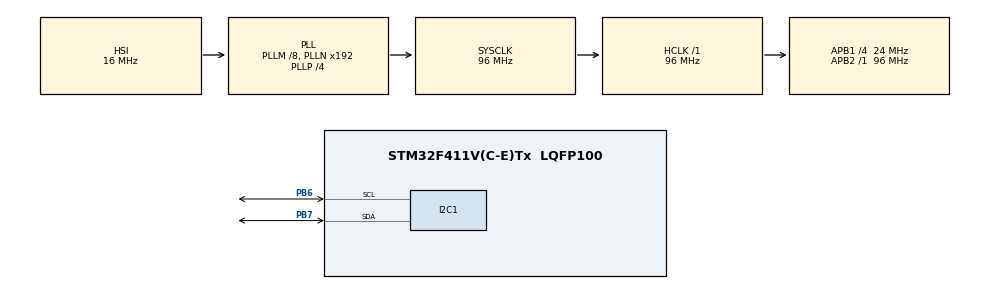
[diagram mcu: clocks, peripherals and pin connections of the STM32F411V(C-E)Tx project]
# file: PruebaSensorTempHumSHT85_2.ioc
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Mcu.Family=STM32F4
Mcu.Name=STM32F411V(C-E)Tx
Mcu.Package=LQFP100
NVIC.PriorityGroup=NVIC_PRIORITYGROUP_0
PB6.GPIO_Pu=GPIO_PULLUP
PB6.Mode=I2C
PB6.Signal=I2C1_SCL
PB7.GPIO_Pu=GPIO_PULLUP
PB7.Mode=I2C
PB7.Signal=I2C1_SDA
ProjectManager.HeapSize=0x200
ProjectManager.StackSize=0x400
ProjectManager.TargetToolchain=STM32CubeIDE
RCC.48MHZClocksFreq_Value=48000000
RCC.AHBFreq_Value=96000000
RCC.APB1CLKDivider=RCC_HCLK_DIV4
RCC.APB1Freq_Value=24000000
RCC.APB1TimFreq_Value=48000000
RCC.APB2Freq_Value=96000000
RCC.APB2TimFreq_Value=96000000
RCC.CortexFreq_Value=96000000
RCC.HCLKFreq_Value=96000000
RCC.HSE_VALUE=8000000
RCC.HSI_VALUE=16000000
RCC.PLLI2SM=5
RCC.PLLI2SN=200
RCC.PLLM=8
RCC.PLLP=RCC_PLLP_DIV4
RCC.PLLQ=8
RCC.SYSCLKFreq_VALUE=96000000
RCC.SYSCLKSource=RCC_SYSCLKSOURCE_PLLCLK
RCC.VCOOutputFreq_Value=384000000
board=STM32F411E-DISCO

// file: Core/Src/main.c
/* USER CODE BEGIN Header */
/* USER CODE END Header */
#include "main.h"

/* USER CODE BEGIN Includes */
#include <stdio.h>
/* USER CODE END Includes */

/* USER CODE BEGIN PD */
// Dirección I2C del SHT85 (ver datasheet para confirmar)
#define SHT85_I2C_ADDR 0x44 << 1 // Cambia si usas otra configuración

// Comando para iniciar la medición
#define SHT85_CMD_MEASURE_HIGHREP 0x2400
/* USER CODE END PD */

I2C_HandleTypeDef hi2c1;

/* USER CODE BEGIN PV */
// Variables globales para Live Expressions
float temperature = 0.0f;
float humidity = 0.0f;
uint16_t temp_raw = 0, hum_raw = 0;
/* USER CODE END PV */

void SystemClock_Config(void);
static void MX_GPIO_Init(void);
static void MX_I2C1_Init(void);
/* USER CODE BEGIN PFP */
void ReadSHT85(float *temperature, float *humidity) {
    uint8_t cmd[2] = {SHT85_CMD_MEASURE_HIGHREP >> 8, SHT85_CMD_MEASURE_HIGHREP & 0xFF};
    uint8_t data[6];

    // Enviar el comando para iniciar la medición
    HAL_I2C_Master_Transmit(&hi2c1, SHT85_I2C_ADDR, cmd, 2, HAL_MAX_DELAY);

    // Esperar unos 10 ms para completar la medición
    HAL_Delay(20);

    // Leer los 6 bytes de datos
    HAL_I2C_Master_Receive(&hi2c1, SHT85_I2C_ADDR, data, 6, HAL_MAX_DELAY);

    // Convertir los datos recibidos
    temp_raw = (data[0] << 8) | data[1];
    hum_raw = (data[3] << 8) | data[4];

    // Calcular temperatura y humedad (según el datasheet del SHT85)
    *temperature = -45 + 175 * ((float)temp_raw / 65535);
    *humidity = 100 * ((float)hum_raw / 65535);
}

/* USER CODE END PFP */

int main(void)
{

  /* MCU Configuration--------------------------------------------------------*/

  /* Reset of all peripherals, Initializes the Flash interface and the Systick. */
  HAL_Init();

  /* Configure the system clock */
  SystemClock_Config();

  /* Initialize all configured peripherals */
  MX_GPIO_Init();
  MX_I2C1_Init();

  /* Infinite loop */
  while (1)
  {
	  ReadSHT85(&temperature, &humidity);

	  HAL_Delay(1000); // Leer cada segundo
  }
}

void SystemClock_Config(void)
{
  RCC_OscInitTypeDef RCC_OscInitStruct = {0};
  RCC_ClkInitTypeDef RCC_ClkInitStruct = {0};

  /** Configure the main internal regulator output voltage
  */
  __HAL_RCC_PWR_CLK_ENABLE();
  __HAL_PWR_VOLTAGESCALING_CONFIG(PWR_REGULATOR_VOLTAGE_SCALE1);

  /** Initializes the RCC Oscillators according to the specified parameters
  * in the RCC_OscInitTypeDef structure.
  */
  RCC_OscInitStruct.OscillatorType = RCC_OSCILLATORTYPE_HSI;
  RCC_OscInitStruct.HSIState = RCC_HSI_ON;
  RCC_OscInitStruct.HSICalibrationValue = RCC_HSICALIBRATION_DEFAULT;
  RCC_OscInitStruct.PLL.PLLState = RCC_PLL_ON;
  RCC_OscInitStruct.PLL.PLLSource = RCC_PLLSOURCE_HSI;
  RCC_OscInitStruct.PLL.PLLM = 8;
  RCC_OscInitStruct.PLL.PLLN = 192;
  RCC_OscInitStruct.PLL.PLLP = RCC_PLLP_DIV4;
  RCC_OscInitStruct.PLL.PLLQ = 8;
  if (HAL_RCC_OscConfig(&RCC_OscInitStruct) != HAL_OK)
  {
    Error_Handler();
  }

  /** Initializes the CPU, AHB and APB buses clocks
  */
  RCC_ClkInitStruct.ClockType = RCC_CLOCKTYPE_HCLK|RCC_CLOCKTYPE_SYSCLK
                              |RCC_CLOCKTYPE_PCLK1|RCC_CLOCKTYPE_PCLK2;
  RCC_ClkInitStruct.SYSCLKSource = RCC_SYSCLKSOURCE_PLLCLK;
  RCC_ClkInitStruct.AHBCLKDivider = RCC_SYSCLK_DIV1;
  RCC_ClkInitStruct.APB1CLKDivider = RCC_HCLK_DIV4;
  RCC_ClkInitStruct.APB2CLKDivider = RCC_HCLK_DIV1;

  if (HAL_RCC_ClockConfig(&RCC_ClkInitStruct, FLASH_LATENCY_3) != HAL_OK)
  {
    Error_Handler();
  }
}

static void MX_I2C1_Init(void)
{

  hi2c1.Instance = I2C1;
  hi2c1.Init.ClockSpeed = 100000;
  hi2c1.Init.DutyCycle = I2C_DUTYCYCLE_2;
  hi2c1.Init.OwnAddress1 = 0;
  hi2c1.Init.AddressingMode = I2C_ADDRESSINGMODE_7BIT;
  hi2c1.Init.DualAddressMode = I2C_DUALADDRESS_DISABLE;
  hi2c1.Init.OwnAddress2 = 0;
  hi2c1.Init.GeneralCallMode = I2C_GENERALCALL_DISABLE;
  hi2c1.Init.NoStretchMode = I2C_NOSTRETCH_DISABLE;
  if (HAL_I2C_Init(&hi2c1) != HAL_OK)
  {
    Error_Handler();
  }

}

static void MX_GPIO_Init(void)
{

  /* GPIO Ports Clock Enable */
  __HAL_RCC_GPIOB_CLK_ENABLE();

}

void Error_Handler(void)
{
}
